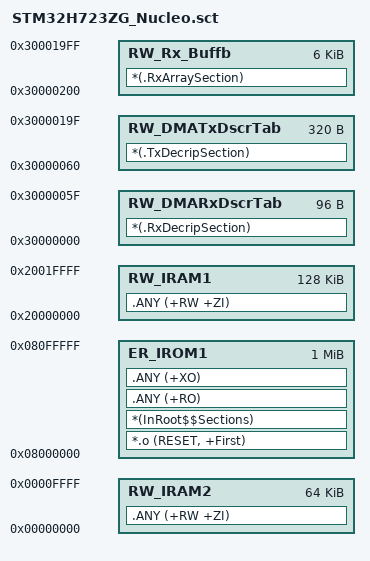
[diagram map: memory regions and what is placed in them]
; *************************************************************
; *** Scatter-Loading Description File generated by uVision ***
; *************************************************************

LR_IROM1 0x08000000 0x00100000  {    ; load region size_region
  ER_IROM1 0x08000000 0x00100000  {  ; load address = execution address
   *.o (RESET, +First)
   *(InRoot$$Sections)
   .ANY (+RO)
   .ANY (+XO)
  }
  RW_IRAM1 0x20000000 0x00020000  {  ; RW data
   .ANY (+RW +ZI)
  }
  RW_IRAM2 0x00000000 0x00010000  {
   .ANY (+RW +ZI)
  }
    RW_DMARxDscrTab 0x30000000 0x60 {
  *(.RxDecripSection)
  }
  RW_DMATxDscrTab 0x30000060 0x140 {
  *(.TxDecripSection)
  }
  RW_Rx_Buffb 0x30000200 0x1800 {
  *(.RxArraySection)
  }
}

